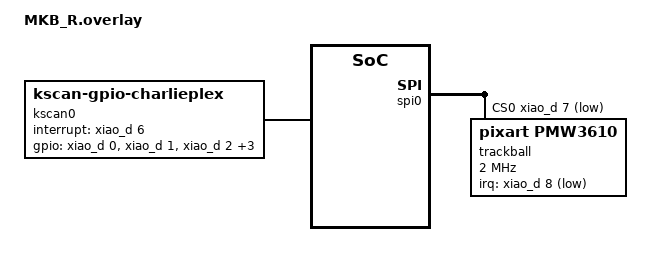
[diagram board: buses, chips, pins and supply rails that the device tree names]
#include <dt-bindings/zmk/bt.h>
#include <input/processors.dtsi>
#include <dt-bindings/zmk/input_transform.h>
#include <zephyr/dt-bindings/input/input-event-codes.h>
#include "MKB_pinctrl_R.dtsi"
#include "MKB.dtsi"

&default_transform {
    col-offset = <6>;
};

/ {
    kscan0: kscan0 {
        compatible = "zmk,kscan-gpio-charlieplex";
        interrupt-gpios = <&xiao_d 6 (GPIO_ACTIVE_HIGH)>;
        gpios
            = <&xiao_d  0 (GPIO_ACTIVE_HIGH)>
            , <&xiao_d  1 (GPIO_ACTIVE_HIGH)>
            , <&xiao_d  2 (GPIO_ACTIVE_HIGH)>
            , <&xiao_d  3 (GPIO_ACTIVE_HIGH)>
            , <&gpio0   9 (GPIO_ACTIVE_HIGH)>
            , <&gpio0  10 (GPIO_ACTIVE_HIGH)>
            ;
    };
};

&spi0 {
    status = "okay";
    cs-gpios =  <&xiao_d 7 GPIO_ACTIVE_LOW>;
    pinctrl-0 = <&spi0_default>;
    pinctrl-1 = <&spi0_sleep>;
    pinctrl-names = "default", "sleep";
    compatible = "nordic,nrf-spim";

    trackball: pd@0 {
        status = "okay";
        compatible = "pixart,pmw3610";
        reg = <0>;
        spi-max-frequency = <2000000>;
        irq-gpios = <&xiao_d 8 (GPIO_ACTIVE_LOW | GPIO_PULL_UP)>;
        cpi = <800>;
        evt-type = <INPUT_EV_REL>;
        x-input-code = <INPUT_REL_X>;
        y-input-code = <INPUT_REL_Y>;
        force-awake;
    };
};

/*input-split*/
/ {
    split_inputs {
        #address-cells = <1>;
        #size-cells = <0>;

        trackball_split: trackball_split@0 {
            compatible = "zmk,input-split";
            status = "okay";
            device = <&trackball>;
            reg = <0>;
        };
    };

    trackball_listener: trackball_listener {
        compatible = "zmk,input-listener";
        status = "okay";
        device = <&trackball_split>;
    };
};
